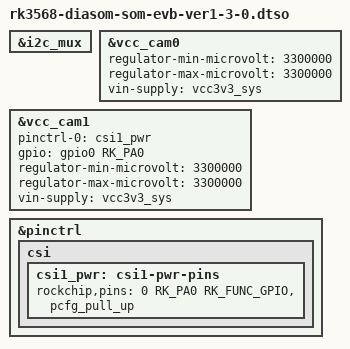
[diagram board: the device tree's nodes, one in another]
/* SPDX-License-Identifier: GPL-2.0+ */
/* SPDX-FileCopyrightText: Alexander Shiyan <shc_work@mail.ru> */

/dts-v1/;
/plugin/;

#include <dt-bindings/gpio/gpio.h>
#include <dt-bindings/pinctrl/rockchip.h>

&i2c_mux {
	status = "okay";
};

&vcc_cam0 {
	regulator-min-microvolt = <3300000>;
	regulator-max-microvolt = <3300000>;
	vin-supply = <&vcc3v3_sys>;
	status = "okay";
};

&vcc_cam1 {
	pinctrl-0 = <&csi1_pwr>;
	gpio = <&gpio0 RK_PA0 GPIO_ACTIVE_HIGH>;
	regulator-min-microvolt = <3300000>;
	regulator-max-microvolt = <3300000>;
	vin-supply = <&vcc3v3_sys>;
	status = "okay";
};

&pinctrl {
	csi {
		csi1_pwr: csi1-pwr-pins {
			rockchip,pins =
				<0 RK_PA0 RK_FUNC_GPIO &pcfg_pull_up>;		/* CSI_PWREN1 */
		};
	};
};
